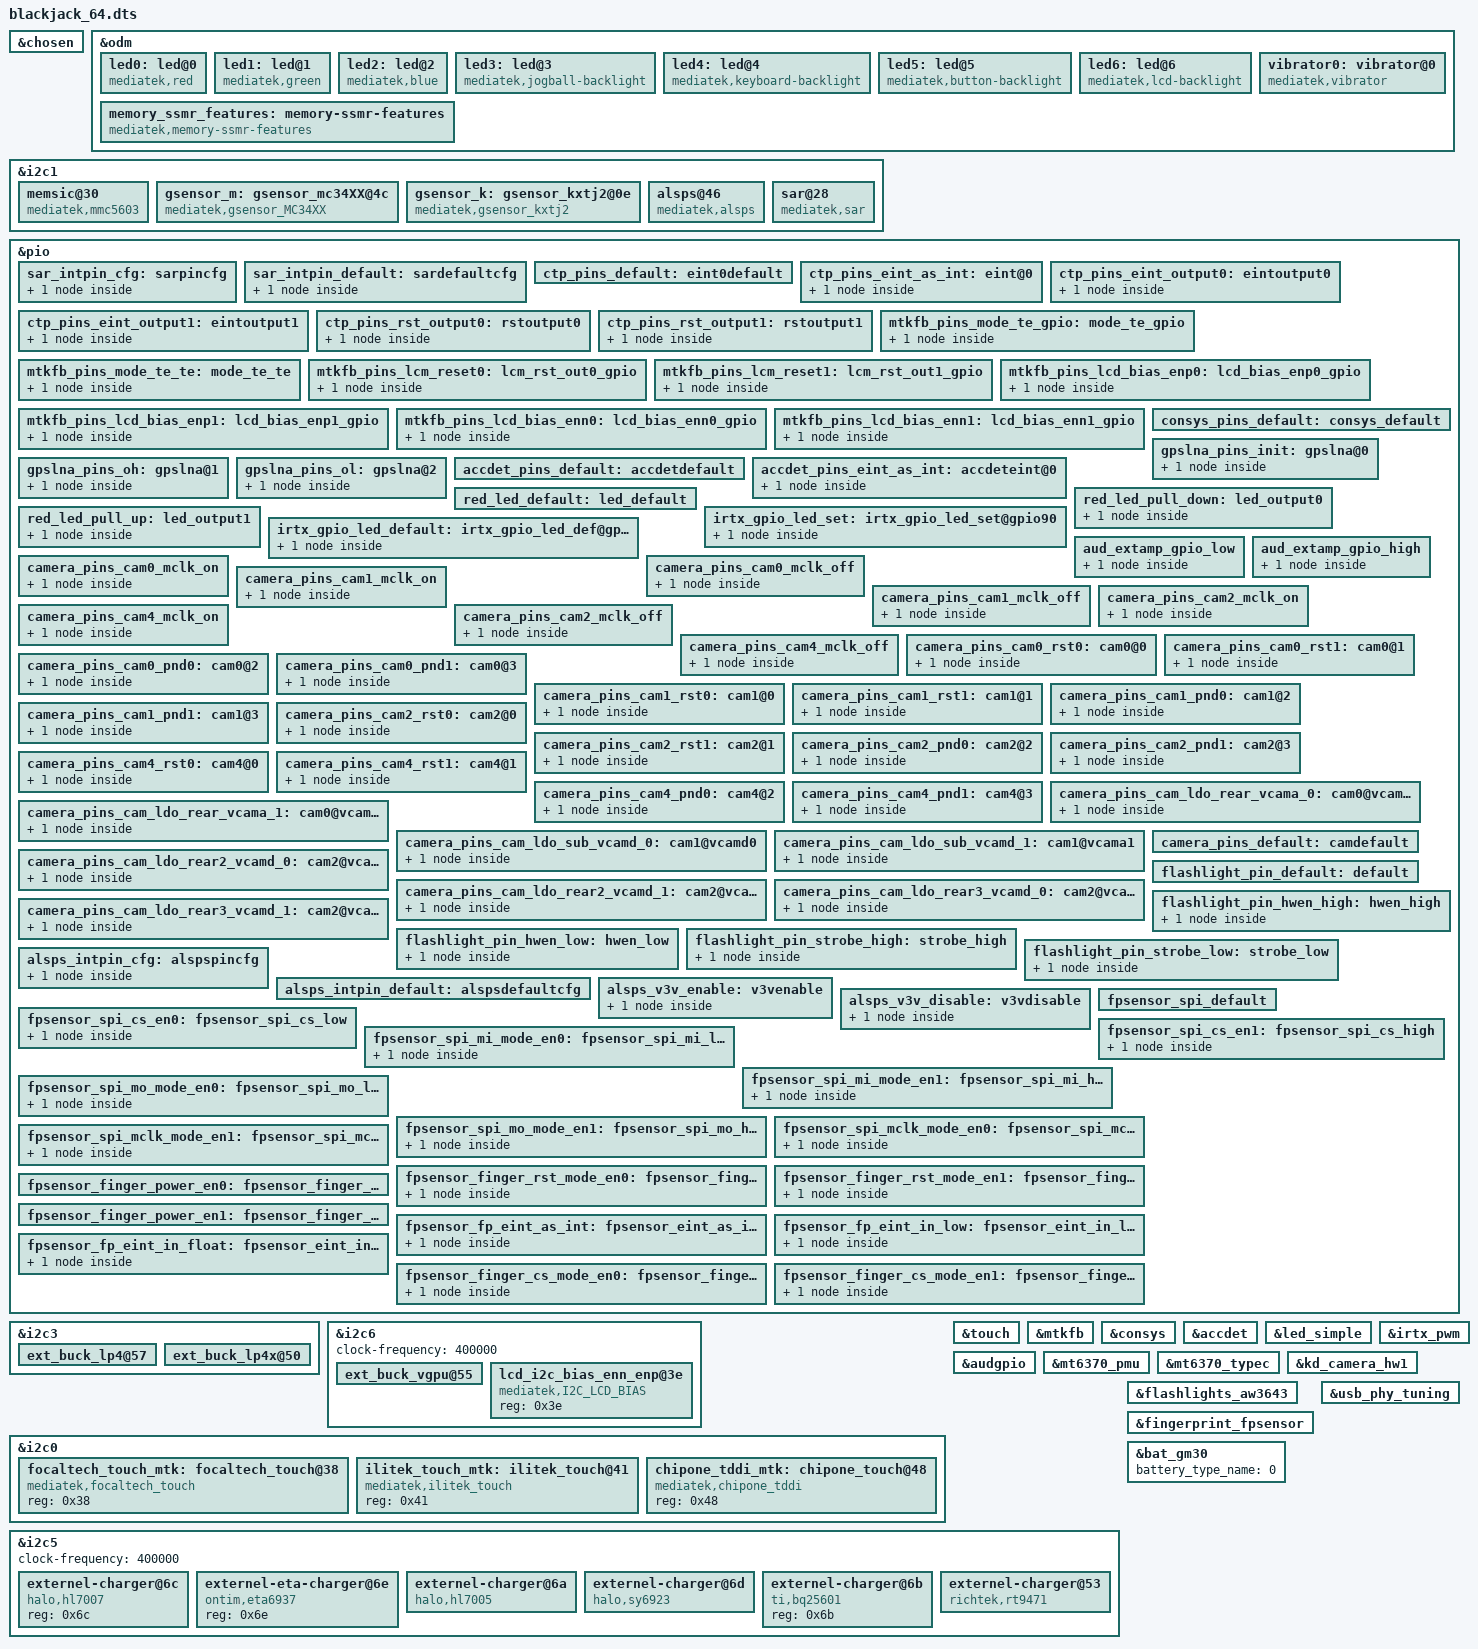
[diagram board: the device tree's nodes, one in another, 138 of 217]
#include <dt-bindings/interrupt-controller/arm-gic.h>
#include <dt-bindings/interrupt-controller/irq.h>
#include <dt-bindings/pinctrl/mt6765-pinfunc.h>
#include <dt-bindings/clock/mt6765-clk.h>

/dts-v1/;
/plugin/;

/* chosen */
&chosen {

	/* fpga may has no lk, we need to specify display info here */
	/* fb buffer is reserved using this dts by memory node above */
	atag,videolfb-fb_base_h = <0x0>;
	atag,videolfb-fb_base_l = <0x5e605000>;
	atag,videolfb-islcmfound = <1>;
	/* because no lk, so lcm is not inited */
	atag,videolfb-islcm_inited = <0>;
	atag,videolfb-fps= <6000>;
	atag,videolfb-vramSize= <0x017bb000>;
	atag,videolfb-lcmname= "nt35695B_fhd_dsi_cmd_auo_rt5081_drv";
};

&odm {
	led0:led@0 {
		compatible = "mediatek,red";
		led_mode = <3>;
		data = <1>;
		pwm_config = <0 0 0 0 0>;
	};
	led1:led@1 {
		compatible = "mediatek,green";
		led_mode = <3>;
		data = <2>;
		pwm_config = <0 0 0 0 0>;
	};
	led2:led@2 {
		compatible = "mediatek,blue";
		led_mode = <0>;
		data = <1>;
		pwm_config = <0 0 0 0 0>;
	};
	led3:led@3 {
		compatible = "mediatek,jogball-backlight";
		led_mode = <0>;
		data = <1>;
		pwm_config = <0 0 0 0 0>;
	};
	led4:led@4 {
		compatible = "mediatek,keyboard-backlight";
		led_mode = <0>;
		data = <1>;
		pwm_config = <0 0 0 0 0>;
	};
	led5:led@5 {
		compatible = "mediatek,button-backlight";
		led_mode = <0>;
		data = <1>;
		pwm_config = <0 0 0 0 0>;
	};
	led6:led@6 {
		compatible = "mediatek,lcd-backlight";
		led_mode = <4>;
		data = <1>;
		pwm_config = <0 2 0 0 0>;
	};
	vibrator0:vibrator@0 {
		compatible = "mediatek,vibrator";
		vib_timer = <25>;
		vib_limit = <9>;
		vib_vol= <0x0b>;
	};

	memory_ssmr_features: memory-ssmr-features {
		compatible = "mediatek,memory-ssmr-features";
		svp-size = <0 0x10000000>;
		iris-recognition-size = <0 0>;
		2d_fr-size = <0 0>;
		tui-size = <0 0>;
		wfd-size = <0 0>;
		prot-sharedmem-size = <0 0>;
	};

};

&i2c1 {
	#address-cells = <1>;
	#size-cells = <0>;

	/* magnetometer sensor */
	memsic@30 {
		compatible = "mediatek,mmc5603";
		reg = <0x30>;
		status = "okay";

		i2c_num = <1>;
		i2c_addr = <0x30 0 0 0>;
		direction = <2>;
		power_id = <0xffff>;
		power_vol = <0>;
		is_batch_supported = <0>;
	};

	gsensor_m:gsensor_mc34XX@4c {
		compatible = "mediatek,gsensor_MC34XX";
		reg = <0x4c>;
		status = "okay";

		i2c_num	= <1>;
		i2c_addr = <0x4c 0 0 0>;
		direction = <1>;
		power_id = <0xffff>;
		power_vol = <0>;
		firlen = <16>;
		is_batch_supported = <1>;
	};

	gsensor_k:gsensor_kxtj2@0e {
		compatible = "mediatek,gsensor_kxtj2";
		reg = <0x0e>;
		status = "okay";

		i2c_num	= <1>;
		i2c_addr = <0x0e 0 0 0>;
		direction = <6>;
		power_id = <0xffff>;
		power_vol = <0>;
		firlen = <16>;
		is_batch_supported = <1>;
	};

	alsps@46 {
		compatible = "mediatek,alsps";
		reg = <0x46>;
		status = "okay";

		pinctrl-names = "pin_default", "pin_cfg", "v3v_enable", "v3v_disable";
		pinctrl-0 = <&alsps_intpin_default>;
		pinctrl-1 = <&alsps_intpin_cfg>;
		pinctrl-2 = <&alsps_v3v_enable>;
		pinctrl-3 = <&alsps_v3v_disable>;

		i2c_num = <1>;
		i2c_addr = <0x46 0 0 0>;
		polling_mode_ps = <0>;
		polling_mode_als = <1>;
		power_id = <0xffff>;
		power_vol = <0>;
		als_level = < 
			0  128   300   482    930    1500    2750   3600
			0  145   335   570    1150   2700    3500   4800
			0  160   420   700    1200   2700    3900   5100
			0  128   300   482    930    1500    2750   3600
			0  145   335   570    1150   2700    3500   4800
			0  160   420   700    1200   2700    3900   5100
		>;
		als_value = < 0  133  304  502   1004  2005  3058   4000 >;
		state_val = <0>;
		psctrl_val = <0x31>;
		alsctrl_val = <0x38>;
		ledctrl_val = <0xFF>;
		wait_val = <0xF>;
		ps_threshold_high = <1700>;
		ps_threshold_low = <1500>;
		is_batch_supported_ps = <0>;
		is_batch_supported_als = <0>;
	};

	sar@28 {
		compatible = "mediatek,sar";
		reg = <0x28>;

		pinctrl-names = "pin_default", "pin_cfg";
		pinctrl-0 = <&sar_intpin_default>;
		pinctrl-1 = <&sar_intpin_cfg>;

		Semtech,reg-num = <46>; /* total registers number to initialize*/
		Semtech,reg-init  = /bits/ 8 < 0x10 0x16
						0x20 0x00
						0x23 0x00
						0x24 0x44
						0x26 0x01
						0x27 0x44
						0x28 0x01 /*PH0 to CS0 input*/
						0x29 0x10
						0x2A 0x19 /*PH2 CS2-input,CS1-dync,CS0-HZ*/
						0x2B 0x00
						0x2C 0x12
						0x2D 0x08
						0x30 0x09
						0x31 0x09
						0x32 0x08
						0x33 0x20
						0x34 0x0C
						0x35 0x00
						0x36 0x1B
						0x37 0x1B
						0x40 0x00
						0x41 0x00
						0x42 0x00
						0x43 0x00
						0x44 0x00
						0x45 0x05
						0x46 0x00
						0x47 0x00
						0x48 0x00
						0x49 0x80
						0x4A 0x00
						0x4B 0x00
						0x4C 0x00
						0x4D 0x00
						0x4E 0x80
						0x4F 0x0C
						0x50 0x00
						0x51 0x70
						0x52 0x20
						0x53 0xE1
						0x54 0xF0
						0x05 0x70
						0x06 0x00
						0x07 0x00
						0x08 0x00
						0x11 0x24>;
	};
};


&pio {
	sar_intpin_cfg: sarpincfg {
		pins_cmd_dat {
			pinmux = <PINMUX_GPIO9__FUNC_GPIO9>;
			slew-rate = <0>;
			bias-pull-up = <MTK_PUPD_SET_R1R0_01>;
		};
	};

	sar_intpin_default: sardefaultcfg {
		pins_cmd_dat {
			pinmux = <PINMUX_GPIO9__FUNC_GPIO9>;
			slew-rate = <0>;
			output-high;
		};
	};
};


&i2c3 {
	ext_buck_lp4@57 {
		regulator-name ="ext_buck_vdd2";
		regulator-min-microvolt = <300000>;
		regulator-max-microvolt = <1300000>;
		vsel_pin = <0>;
	};

	ext_buck_lp4x@50 {
		regulator-name ="ext_buck_vddq";
		regulator-min-microvolt = <300000>;
		regulator-max-microvolt = <1300000>;
		vsel_pin = <1>;
	};
};

&i2c6 {
	ext_buck_vgpu@55 {
		regulator-name ="ext_buck_vgpu";
		regulator-min-microvolt = <300000>;
		regulator-max-microvolt = <1300000>;
		vsel_pin = <2>;
	};
};
/* TOUCH start */
&i2c0 {
        #address-cells = <1>;
        #size-cells = <0>;
        clock-frequency = <400000>;
        mediatek,use-open-drain;
        focaltech_touch_mtk:focaltech_touch@38 {
                compatible = "mediatek,focaltech_touch";
                reg = <0x38>;
                status = "okay";
        };
        ilitek_touch_mtk:ilitek_touch@41 {
                compatible = "mediatek,ilitek_touch";
                reg = <0x41>;
                status = "okay";
        };
        chipone_tddi_mtk:chipone_touch@48 {
                compatible = "mediatek,chipone_tddi";
                reg = <0x48>;
                status = "okay";
        };

};

&touch {
	tpd-resolution = <720 1560>;
	use-tpd-button = <0>;
	tpd-key-num = <3>;
	tpd-key-local= <139 172 158 0>;
	tpd-key-dim-local = <90 883 100 40 230
				 883 100 40 370 883 100 40 0 0 0 0>;
	tpd-max-touch-num = <10>;
	tpd-filter-enable = <1>;
	tpd-filter-pixel-density = <106>;
	tpd-filter-custom-prameters = <0 0 0 0 0 0 0 0 0 0 0 0>;
	tpd-filter-custom-speed = <0 0 0>;
	pinctrl-names = "default", "state_eint_as_int", "state_eint_output0",
		"state_eint_output1", "state_rst_output0", "state_rst_output1";
	pinctrl-0 = <&ctp_pins_default>;
	pinctrl-1 = <&ctp_pins_eint_as_int>;
	pinctrl-2 = <&ctp_pins_eint_output0>;
	pinctrl-3 = <&ctp_pins_eint_output1>;
	pinctrl-4 = <&ctp_pins_rst_output0>;
	pinctrl-5 = <&ctp_pins_rst_output1>;
	status = "okay";
};
&pio {
	ctp_pins_default: eint0default {
	};
	ctp_pins_eint_as_int: eint@0 {
		pins_cmd_dat {
			pinmux = <PINMUX_GPIO0__FUNC_GPIO0>;
			slew-rate = <0>;
			bias-disable;
		};
	};
	ctp_pins_eint_output0: eintoutput0 {
		pins_cmd_dat {
			pinmux = <PINMUX_GPIO0__FUNC_GPIO0>;
			slew-rate = <1>;
			output-low;
		};
	};
	ctp_pins_eint_output1: eintoutput1 {
		pins_cmd_dat {
			pinmux = <PINMUX_GPIO0__FUNC_GPIO0>;
			slew-rate = <1>;
			output-high;
		};
	};
	ctp_pins_rst_output0: rstoutput0 {
		pins_cmd_dat {
			pinmux = <PINMUX_GPIO174__FUNC_GPIO174>;
			slew-rate = <1>;
			output-low;
		};
	};
	ctp_pins_rst_output1: rstoutput1 {
		pins_cmd_dat {
			pinmux = <PINMUX_GPIO174__FUNC_GPIO174>;
			slew-rate = <1>;
			output-high;
		};
	};
};
/* TOUCH end */

&i2c6 {
	#address-cells = <1>;
	#size-cells = <0>;
	clock-frequency = <400000>;

	lcd_i2c_bias_enn_enp@3e{
		compatible = "mediatek,I2C_LCD_BIAS";
		reg = <0x3e>;
		status = "okay";
	};
};

/* DISPSYS GPIO standardization */
&pio {
	mtkfb_pins_mode_te_gpio: mode_te_gpio {
		pins_cmd_dat {
			pinmux = <PINMUX_GPIO44__FUNC_DSI_TE>;
		};
	};

	mtkfb_pins_mode_te_te: mode_te_te {
		pins_cmd_dat {
			pinmux = <PINMUX_GPIO44__FUNC_DSI_TE>;
		};
	};

	mtkfb_pins_lcm_reset0: lcm_rst_out0_gpio {
		pins_cmd_dat {
			pinmux = <PINMUX_GPIO45__FUNC_GPIO45>;
			slew-rate = <1>;
			output-low;
		};
	};

	mtkfb_pins_lcm_reset1: lcm_rst_out1_gpio {
		pins_cmd_dat {
			pinmux = <PINMUX_GPIO45__FUNC_GPIO45>;
			slew-rate = <1>;
			output-high;
		};
	};

	mtkfb_pins_lcd_bias_enp0: lcd_bias_enp0_gpio {
		pins_cmd_dat {
			pinmux = <PINMUX_GPIO172__FUNC_GPIO172>;
			slew-rate = <1>;
			output-low;
		};
	};
	mtkfb_pins_lcd_bias_enp1: lcd_bias_enp1_gpio {
		pins_cmd_dat {
			pinmux = <PINMUX_GPIO172__FUNC_GPIO172>;
			slew-rate = <1>;
			output-high;
		};
	};

	mtkfb_pins_lcd_bias_enn0: lcd_bias_enn0_gpio {
		pins_cmd_dat {
			pinmux = <PINMUX_GPIO173__FUNC_GPIO173>;
			slew-rate = <1>;
			output-low;
		};
	};
	mtkfb_pins_lcd_bias_enn1: lcd_bias_enn1_gpio {
		pins_cmd_dat {
			pinmux = <PINMUX_GPIO173__FUNC_GPIO173>;
			slew-rate = <1>;
			output-high;
		};
	};

};

&mtkfb {
	pinctrl-names = "mode_te_gpio", "mode_te_te", "lcm_rst_out0_gpio",
		"lcm_rst_out1_gpio","lcd_bias_enp0_gpio", "lcd_bias_enp1_gpio", "lcd_bias_enn0_gpio", "lcd_bias_enn1_gpio";
	pinctrl-0 = <&mtkfb_pins_mode_te_gpio>;
	pinctrl-1 = <&mtkfb_pins_mode_te_te>;
	pinctrl-2 = <&mtkfb_pins_lcm_reset0>;
	pinctrl-3 = <&mtkfb_pins_lcm_reset1>;
	pinctrl-4 = <&mtkfb_pins_lcd_bias_enp0>;
	pinctrl-5 = <&mtkfb_pins_lcd_bias_enp1>;
	pinctrl-6 = <&mtkfb_pins_lcd_bias_enn0>;
	pinctrl-7 = <&mtkfb_pins_lcd_bias_enn1>;
	status = "okay";
};
/* DISPSYS GPIO standardization end */
/* CONSYS GPIO standardization */
&pio {
	consys_pins_default: consys_default {
	};
	gpslna_pins_init: gpslna@0 {
		pins_cmd_dat {
			pinmux = <PINMUX_GPIO91__FUNC_GPIO91>;
			slew-rate = <0>;
			bias-disable;
			output-low;
		};
	};
	gpslna_pins_oh: gpslna@1 {
		pins_cmd_dat {
			pinmux = <PINMUX_GPIO91__FUNC_GPIO91>;
			slew-rate = <1>;
			output-high;
		};
	};
	gpslna_pins_ol: gpslna@2 {
		pins_cmd_dat {
			pinmux = <PINMUX_GPIO91__FUNC_GPIO91>;
			slew-rate = <1>;
			output-low;
		};
	};
};
&consys {
	pinctrl-names = "default", "gps_lna_state_init",
		"gps_lna_state_oh", "gps_lna_state_ol";
	pinctrl-0 = <&consys_pins_default>;
	pinctrl-1 = <&gpslna_pins_init>;
	pinctrl-2 = <&gpslna_pins_oh>;
	pinctrl-3 = <&gpslna_pins_ol>;
	status = "okay";
};
/* CONSYS end */

/* accdet start */
&accdet {
	accdet-mic-vol = <6>;
	headset-mode-setting = <0x500 0x500 1 0x1f0 0x800 0x800 0x20 0x44>;
	accdet-plugout-debounce = <1>;
	accdet-mic-mode = <1>;
	headset-eint-level-pol = <8>;
	headset-three-key-threshold = <0 80 175 400>;
	headset-three-key-threshold-CDD = <0 121 192 600>;
	headset-four-key-threshold = <0 58 121 192 400>;
	pinctrl-names = "default", "state_eint_as_int";
	pinctrl-0 = <&accdet_pins_default>;
	pinctrl-1 = <&accdet_pins_eint_as_int>;
	status = "okay";
};
&pio {
	accdet_pins_default: accdetdefault {
	};
	accdet_pins_eint_as_int: accdeteint@0 {
		pins_cmd_dat {
			pinmux = <PINMUX_GPIO9__FUNC_GPIO9>;
			slew-rate = <0>;
			bias-disable;
		};
	};
};
/* accdet end */

&led_simple {
	pinctrl-names = "default", "red_led_output0", "red_led_output1";
	pinctrl-0 = <&red_led_default>;
	pinctrl-1 = <&red_led_pull_down>;
	pinctrl-2 = <&red_led_pull_up>;
	status = "okay";
};
&pio {
	red_led_default: led_default {
				 };
	red_led_pull_down: led_output0 {
		pins_cmd_dat {
			pinmux = <PINMUX_GPIO159__FUNC_GPIO159>;
			slew-rate = <1>;
			output-low;
		};
	};
	red_led_pull_up: led_output1 {
		pins_cmd_dat {
			pinmux = <PINMUX_GPIO159__FUNC_GPIO159>;
			slew-rate = <1>;
			output-high;
		};
	};
};
/* IRTX GPIO end */
&irtx_pwm {
	pinctrl-names = "irtx_gpio_led_default", "irtx_gpio_led_set";
	pinctrl-0 = <&irtx_gpio_led_default>;
	pinctrl-1 = <&irtx_gpio_led_set>;
	status = "okay";
};
&pio {
	irtx_gpio_led_default:irtx_gpio_led_def@gpio90 {
		pins_cmd_dat {
			pinmux = <PINMUX_GPIO90__FUNC_GPIO90>;
			slew-rate = <1>;
			bias-disable;
			output-low;
			input-schmitt-enable = <0>;
		};
	};

	irtx_gpio_led_set:irtx_gpio_led_set@gpio90 {
		pins_cmd_dat {
			pinmux = <PINMUX_GPIO90__FUNC_PWM0>;
			slew-rate = <1>;
			output-high;
		};
	};
};
/* IRTX GPIO Settings -End */

/* AUDIO GPIO standardization */
&audgpio {
		pinctrl-names = "extamp-pulllow",
				"extamp-pullhigh";
		pinctrl-0 = <&aud_extamp_gpio_low>;
		pinctrl-1 = <&aud_extamp_gpio_high>;
		status = "okay";
	};
	
	&pio {
	
		aud_extamp_gpio_low: aud_extamp_gpio_low {
			pins_gpio_low {
				pinmux = <PINMUX_GPIO153__FUNC_GPIO153>;
				out-enable;
				slew-rate = <2>;
				bias-disable;
				output-low;
			};
		};
	
		aud_extamp_gpio_high: aud_extamp_gpio_high {
			pins_gpio_high {
				pinmux = <PINMUX_GPIO153__FUNC_GPIO153>;
				out-enable;
				slew-rate = <2>;
				bias-disable;
				output-high;
			};
		};
};

/* AUDIO end */

&mt6370_pmu {
	mt6370,intr_gpio_num = <11>; /* direct defined GPIO num */
	mt6370,intr_gpio = <&pio 11 0x0>;
};

&mt6370_typec {
	mt6370pd,intr_gpio_num = <41>; /* direct defined GPIO num */
	mt6370pd,intr_gpio = <&pio 41 0x0>;
};

&i2c5 {
	#address-cells = <1>;
	#size-cells = <0>;
	clock-frequency = <400000>;

	externel-charger@6c{
		compatible = "halo,hl7007";
		reg = <0x6c>;
		status = "okay";
	};
       externel-eta-charger@6e{
               compatible = "ontim,eta6937";
               reg = <0x6e>;/*dumy addr,in fact ,the addr is 0x6b-1*/
               status = "okay";
       };
	externel-charger@6a{
		compatible = "halo,hl7005";
		reg = <0x6a>;
		status = "okay";
		ichg = <1050000>; /* uA */
	};
	externel-charger@6d{
		compatible = "halo,sy6923";
		reg = <0x6d>;
		status = "okay";
		ichg = <1050000>; /* uA */
	};
	externel-charger@6b{
		compatible = "ti,bq25601";
		reg = <0x6b>;
		status = "okay";
	};
	externel-charger@53{
		compatible = "richtek,rt9471";
		reg = <0x53>;
		status = "okay";
		ichg = <2000000>; /* uA */
	};
};
&pio {
	camera_pins_cam0_mclk_on: camera_pins_cam0_mclk_on {
		pins_cmd_dat {
			pinmux = <PINMUX_GPIO99__FUNC_CMMCLK0>;
		};
	};
	camera_pins_cam0_mclk_off: camera_pins_cam0_mclk_off {
		pins_cmd_dat {
			pinmux = <PINMUX_GPIO99__FUNC_GPIO99>;
		};
	};
	camera_pins_cam1_mclk_on: camera_pins_cam1_mclk_on {
		pins_cmd_dat {
			pinmux = <PINMUX_GPIO100__FUNC_CMMCLK1>;
		};
	};
	camera_pins_cam1_mclk_off: camera_pins_cam1_mclk_off {
		pins_cmd_dat {
			pinmux = <PINMUX_GPIO100__FUNC_GPIO100>;
		};
	};
	camera_pins_cam2_mclk_on: camera_pins_cam2_mclk_on {
		pins_cmd_dat {
			pinmux = <PINMUX_GPIO88__FUNC_CMMCLK3>;
		};
	};
	camera_pins_cam2_mclk_off: camera_pins_cam2_mclk_off {
		pins_cmd_dat {
			pinmux = <PINMUX_GPIO88__FUNC_GPIO88>;
		};
	};
	camera_pins_cam4_mclk_on: camera_pins_cam4_mclk_on {
		pins_cmd_dat {
			pinmux = <PINMUX_GPIO108__FUNC_CMMCLK2>;
		};
	};
	camera_pins_cam4_mclk_off: camera_pins_cam4_mclk_off {
		pins_cmd_dat {
			pinmux = <PINMUX_GPIO108__FUNC_GPIO108>;
		};
	};
	camera_pins_cam0_rst0: cam0@0 {
		pins_cmd_dat {
			pinmux = <PINMUX_GPIO101__FUNC_GPIO101>;
			slew-rate = <1>;
			output-low;
		};
	};
	camera_pins_cam0_rst1: cam0@1 {
		pins_cmd_dat {
			pinmux = <PINMUX_GPIO101__FUNC_GPIO101>;
			slew-rate = <1>;
			output-high;
		};
	};
	camera_pins_cam0_pnd0: cam0@2 {
		pins_cmd_dat {
			pinmux = <PINMUX_GPIO97__FUNC_GPIO97>;
			slew-rate = <1>;
			output-low;
		};
	};
	camera_pins_cam0_pnd1: cam0@3 {
		pins_cmd_dat {
			pinmux = <PINMUX_GPIO97__FUNC_GPIO97>;
			slew-rate = <1>;
			output-high;
		};
	};
	camera_pins_cam1_rst0: cam1@0 {
		pins_cmd_dat {
			pinmux = <PINMUX_GPIO102__FUNC_GPIO102>;
			slew-rate = <1>;
			output-low;
		};
	};
	camera_pins_cam1_rst1: cam1@1 {
		pins_cmd_dat {
			pinmux = <PINMUX_GPIO102__FUNC_GPIO102>;
			slew-rate = <1>;
			output-high;
		};
	};
	camera_pins_cam1_pnd0: cam1@2 {
		pins_cmd_dat {
			pinmux = <PINMUX_GPIO98__FUNC_GPIO98>;
			slew-rate = <1>;
			output-low;
		};
	};
	camera_pins_cam1_pnd1: cam1@3 {
		pins_cmd_dat {
			pinmux = <PINMUX_GPIO98__FUNC_GPIO98>;
			slew-rate = <1>;
			output-high;
		};
	};
	camera_pins_cam2_rst0: cam2@0 {
		pins_cmd_dat {
			pinmux = <PINMUX_GPIO87__FUNC_GPIO87>;
			slew-rate = <1>;
			output-low;
		};
	};
	camera_pins_cam2_rst1: cam2@1 {
		pins_cmd_dat {
			pinmux = <PINMUX_GPIO87__FUNC_GPIO87>;
			slew-rate = <1>;
			output-high;
		};
	};
	camera_pins_cam2_pnd0: cam2@2 {
		pins_cmd_dat {
			pinmux = <PINMUX_GPIO160__FUNC_GPIO160>;
			slew-rate = <1>;
			output-low;
		};
	};
	camera_pins_cam2_pnd1: cam2@3 {
		pins_cmd_dat {
			pinmux = <PINMUX_GPIO160__FUNC_GPIO160>;
			slew-rate = <1>;
			output-high;
		};
	};
	camera_pins_cam4_rst0: cam4@0 {
		pins_cmd_dat {
			pinmux = <PINMUX_GPIO109__FUNC_GPIO109>;
			slew-rate = <1>;
			output-low;
		};
	};
	camera_pins_cam4_rst1: cam4@1 {
		pins_cmd_dat {
			pinmux = <PINMUX_GPIO109__FUNC_GPIO109>;
			slew-rate = <1>;
			output-high;
		};
	};
	camera_pins_cam4_pnd0: cam4@2 {
		pins_cmd_dat {
			pinmux = <PINMUX_GPIO107__FUNC_GPIO107>;
			slew-rate = <1>;
			output-low;
		};
	};
	camera_pins_cam4_pnd1: cam4@3 {
		pins_cmd_dat {
			pinmux = <PINMUX_GPIO107__FUNC_GPIO107>;
			slew-rate = <1>;
			output-high;
		};
	};
	camera_pins_cam_ldo_rear_vcama_0: cam0@vcamd0 {
		pins_cmd_dat {
			pinmux = <PINMUX_GPIO21__FUNC_GPIO21>;
			slew-rate = <1>;
			output-low;
		};
	};
	camera_pins_cam_ldo_rear_vcama_1: cam0@vcamd1 {
		pins_cmd_dat {
			pinmux = <PINMUX_GPIO21__FUNC_GPIO21>;
			slew-rate = <1>;
			output-high;
		};
	};
	camera_pins_cam_ldo_sub_vcamd_0: cam1@vcamd0 {
		pins_cmd_dat {
			pinmux = <PINMUX_GPIO24__FUNC_GPIO24>;
			slew-rate = <1>;
			output-low;
		};
	};
	camera_pins_cam_ldo_sub_vcamd_1: cam1@vcama1 {
		pins_cmd_dat {
			pinmux = <PINMUX_GPIO24__FUNC_GPIO24>;
			slew-rate = <1>;
			output-high;
		};
	};
	camera_pins_cam_ldo_rear2_vcamd_0: cam2@vcama0 {
		pins_cmd_dat {
			pinmux = <PINMUX_GPIO24__FUNC_GPIO24>;
			slew-rate = <1>;
			output-low;
		};
	};
	camera_pins_cam_ldo_rear2_vcamd_1: cam2@vcama1 {
		pins_cmd_dat {
			pinmux = <PINMUX_GPIO24__FUNC_GPIO24>;
			slew-rate = <1>;
			output-high;
		};
	};
	camera_pins_cam_ldo_rear3_vcamd_0: cam2@vcamd0 {
		pins_cmd_dat {
			pinmux = <PINMUX_GPIO24__FUNC_GPIO24>;
			slew-rate = <1>;
			output-low;
		};
	};
	camera_pins_cam_ldo_rear3_vcamd_1: cam2@vcamd1 {
		pins_cmd_dat {
			pinmux = <PINMUX_GPIO24__FUNC_GPIO24>;
			slew-rate = <1>;
			output-high;
		};
	};
	camera_pins_default: camdefault {
	};

};

&kd_camera_hw1 {
	pinctrl-names = "default",
			"cam0_rst0",
			"cam0_rst1",
			"cam0_pnd0",
			"cam0_pnd1",
			"cam1_rst0",
			"cam1_rst1",
			"cam1_pnd0",
			"cam1_pnd1",
			"cam2_rst0",
			"cam2_rst1",
			"cam2_pnd0",
			"cam2_pnd1",
			"cam4_rst0",
			"cam4_rst1",
			"cam4_pnd0",
			"cam4_pnd1",
			"cam0_vcama_on",
			"cam0_vcama_off",
			"cam1_vcamd_on",
			"cam1_vcamd_off",
			"cam2_vcamd_on",
			"cam2_vcamd_off",
			"cam4_vcamd_on",
			"cam4_vcamd_off",
			"cam0_mclk_on",
			"cam0_mclk_off",
			"cam1_mclk_on",
			"cam1_mclk_off",
			"cam2_mclk_on",
			"cam2_mclk_off",
			"cam4_mclk_on",
			"cam4_mclk_off";

	pinctrl-0 = <&camera_pins_default>;
	pinctrl-1 = <&camera_pins_cam0_rst0>;
	pinctrl-2 = <&camera_pins_cam0_rst1>;
	pinctrl-3 = <&camera_pins_cam0_pnd0>;
	pinctrl-4 = <&camera_pins_cam0_pnd1>;
	pinctrl-5 = <&camera_pins_cam1_rst0>;
	pinctrl-6 = <&camera_pins_cam1_rst1>;
	pinctrl-7 = <&camera_pins_cam1_pnd0>;
	pinctrl-8 = <&camera_pins_cam1_pnd1>;
	pinctrl-9 = <&camera_pins_cam2_rst0>;
	pinctrl-10 = <&camera_pins_cam2_rst1>;
	pinctrl-11 = <&camera_pins_cam2_pnd0>;
	pinctrl-12 = <&camera_pins_cam2_pnd1>;
	pinctrl-13 = <&camera_pins_cam4_rst0>;
	pinctrl-14 = <&camera_pins_cam4_rst1>;
	pinctrl-15 = <&camera_pins_cam4_pnd0>;
	pinctrl-16 = <&camera_pins_cam4_pnd1>;
	pinctrl-17 = <&camera_pins_cam_ldo_rear_vcama_1>;
	pinctrl-18 = <&camera_pins_cam_ldo_rear_vcama_0>;
	pinctrl-19 = <&camera_pins_cam_ldo_sub_vcamd_1>;
	pinctrl-20 = <&camera_pins_cam_ldo_sub_vcamd_0>;
	pinctrl-21 = <&camera_pins_cam_ldo_rear2_vcamd_1>;
	pinctrl-22 = <&camera_pins_cam_ldo_rear2_vcamd_0>;
	pinctrl-23 = <&camera_pins_cam_ldo_rear3_vcamd_1>;
	pinctrl-24 = <&camera_pins_cam_ldo_rear3_vcamd_0>;
	pinctrl-25 = <&camera_pins_cam0_mclk_on>;
	pinctrl-26 = <&camera_pins_cam0_mclk_off>;
	pinctrl-27 = <&camera_pins_cam1_mclk_on>;
	pinctrl-28 = <&camera_pins_cam1_mclk_off>;
	pinctrl-29 = <&camera_pins_cam2_mclk_on>;
	pinctrl-30 = <&camera_pins_cam2_mclk_off>;
	pinctrl-31 = <&camera_pins_cam4_mclk_on>;
	pinctrl-32 = <&camera_pins_cam4_mclk_off>;
	status = "okay";

};
 /* flashlight begin */
 
&pio{
     flashlight_pin_default: default{};

     flashlight_pin_hwen_high: hwen_high{
         pins_cmd_dat {
             pinmux = <PINMUX_GPIO151__FUNC_GPIO151>;
             slew-rate = <1>;
             output-high;
         };
    };

     flashlight_pin_hwen_low: hwen_low{
         pins_cmd_dat{
             pinmux = <PINMUX_GPIO151__FUNC_GPIO151>;
             slew-rate = <1>;
            output-low;
         };
     };
     flashlight_pin_strobe_high: strobe_high{
         pins_cmd_dat {
             pinmux = <PINMUX_GPIO150__FUNC_GPIO150>;
             slew-rate = <1>;
             output-high;
         };
     };

     flashlight_pin_strobe_low: strobe_low{
         pins_cmd_dat{
             pinmux = <PINMUX_GPIO150__FUNC_GPIO150>;
             slew-rate = <1>;
             output-low;
         };
     };
};

&flashlights_aw3643{
     pinctrl-names = "default", "hwen_high", "hwen_low", "strobe_high", "strobe_low";
     pinctrl-0 = <&flashlight_pin_default>;
     pinctrl-1 = <&flashlight_pin_hwen_high>;
     pinctrl-2 = <&flashlight_pin_hwen_low>;
     pinctrl-3 = <&flashlight_pin_strobe_high>;
     pinctrl-4 = <&flashlight_pin_strobe_low>;
     status = "okay";
};

&pio {
        alsps_intpin_cfg: alspspincfg {

                pins_cmd_dat {
                        pinmux = <PINMUX_GPIO6__FUNC_GPIO6>;
                        slew-rate = <0>;
                        bias-pull-up = <MTK_PUPD_SET_R1R0_01>;
                };
        };

        alsps_intpin_default: alspsdefaultcfg {

        };

        alsps_v3v_enable: v3venable {
                pins_cmd_dat {
                        pinmux = <PINMUX_GPIO154__FUNC_GPIO154>;
                        slew-rate = <1>;
                        output-high;
                };
        };
        alsps_v3v_disable: v3vdisable {
                pins_cmd_dat {
                        pinmux = <PINMUX_GPIO154__FUNC_GPIO154>;
                        slew-rate = <1>;
                        output-low;
                };
        };
};
&pio{
	fpsensor_spi_default: fpsensor_spi_default {
	};

	fpsensor_spi_cs_en0: fpsensor_spi_cs_low {
		pins_cmd_dat {
			pinmux = <PINMUX_GPIO26__FUNC_SPI1_A_CSB>;
			slew-rate = <1>;
			output-low;
		};
	};
	fpsensor_spi_cs_en1: fpsensor_spi_cs_high {
		pins_cmd_dat {
			pinmux = <PINMUX_GPIO26__FUNC_SPI1_A_CSB>;
			slew-rate = <1>;
			output-high;
		};
	};
	fpsensor_spi_mi_mode_en0: fpsensor_spi_mi_low {
		pins_cmd_dat {
			pinmux = <PINMUX_GPIO25__FUNC_SPI1_A_MI>;
			slew-rate = <0>;
			bias-pull-up = <00>;
		};
	};
	fpsensor_spi_mi_mode_en1: fpsensor_spi_mi_high {
		pins_cmd_dat {
			pinmux = <PINMUX_GPIO25__FUNC_SPI1_A_MI>;
			bias-disable;
		};
	};
	fpsensor_spi_mo_mode_en0: fpsensor_spi_mo_low {
		pins_cmd_dat {
			pinmux = <PINMUX_GPIO27__FUNC_SPI1_A_MO>;
			slew-rate = <1>;
			output-low;
		};
	};
	fpsensor_spi_mo_mode_en1: fpsensor_spi_mo_high {
		pins_cmd_dat {
			pinmux = <PINMUX_GPIO27__FUNC_SPI1_A_MO>;
			slew-rate = <1>;
			output-high;
		};
	};
	fpsensor_spi_mclk_mode_en0: fpsensor_spi_mclk_low {
		pins_cmd_dat {
			pinmux = <PINMUX_GPIO28__FUNC_SPI1_A_CLK>;
			slew-rate = <1>;
			output-low;
		};
	};
	fpsensor_spi_mclk_mode_en1: fpsensor_spi_mclk_high {
		pins_cmd_dat {
			pinmux = <PINMUX_GPIO28__FUNC_SPI1_A_CLK>;
			slew-rate = <1>;
			output-high;
		};
	};
	fpsensor_finger_rst_mode_en0: fpsensor_finger_rst_low {
		pins_cmd_dat {
			pinmux = <PINMUX_GPIO22__FUNC_GPIO22>;
			slew-rate = <1>;
			output-low;
		};
	};
	fpsensor_finger_rst_mode_en1: fpsensor_finger_rst_high {
		pins_cmd_dat {
			pinmux = <PINMUX_GPIO22__FUNC_GPIO22>;
			slew-rate = <1>;
			output-high;
		};
	};
	fpsensor_finger_power_en0: fpsensor_finger_power_low {
	};

	fpsensor_finger_power_en1: fpsensor_finger_power_high {
	};

	fpsensor_fp_eint_as_int: fpsensor_eint_as_int {
		pins_cmd_dat {
			pinmux = <PINMUX_GPIO5__FUNC_GPIO5>;
			slew-rate = <0>;
			//bias-disable;
			bias-pull-down = <00>;
		};
	};
	fpsensor_fp_eint_in_low: fpsensor_eint_in_low {
		pins_cmd_dat {
			pinmux = <PINMUX_GPIO5__FUNC_GPIO5>;
			slew-rate = <0>;
			bias-pull-down = <00>;
		};
	};
	fpsensor_fp_eint_in_float: fpsensor_eint_in_float {
		pins_cmd_dat {
			pinmux = <PINMUX_GPIO5__FUNC_GPIO5>;
			slew-rate = <0>;
			bias-disable;
		};
	};
	fpsensor_finger_cs_mode_en0: fpsensor_finger_cs_low {
		pins_cmd_dat {
			pinmux = <PINMUX_GPIO26__FUNC_SPI1_A_CSB>;
			slew-rate = <1>;
			output-low;
			input-schmitt-enable = <0>;
		};
	};
	fpsensor_finger_cs_mode_en1: fpsensor_finger_cs_high {
		pins_cmd_dat {
			pinmux = <PINMUX_GPIO26__FUNC_SPI1_A_CSB>;
			slew-rate = <1>;
			output-high;
			input-schmitt-enable = <0>;
		 };
	};
};

&fingerprint_fpsensor{
	pinctrl-names = "fpsensor_spi_default", "fpsensor_spi_cs_low","fpsensor_spi_cs_high","fpsensor_spi_mi_low","fpsensor_spi_mi_high",
		"fpsensor_spi_mo_low","fpsensor_spi_mo_high","fpsensor_spi_mclk_low","fpsensor_spi_mclk_high",
		"fpsensor_finger_rst_low","fpsensor_finger_rst_high","fpsensor_finger_power_low","fpsensor_finger_power_high",
		"fpsensor_eint_as_int","fpsensor_eint_in_low","fpsensor_eint_in_float","fpsensor_finger_cs_low","fpsensor_finger_cs_high";

	pinctrl-0 = <&fpsensor_spi_default>;
	pinctrl-1 = <&fpsensor_spi_cs_en0>;
	pinctrl-2 = <&fpsensor_spi_cs_en1>;
	pinctrl-3 = <&fpsensor_spi_mi_mode_en0>;
	pinctrl-4 = <&fpsensor_spi_mi_mode_en1>;
	pinctrl-5 = <&fpsensor_spi_mo_mode_en0>;
	pinctrl-6 = <&fpsensor_spi_mo_mode_en1>;
	pinctrl-7 = <&fpsensor_spi_mclk_mode_en0>;
	pinctrl-8 = <&fpsensor_spi_mclk_mode_en1>;

	pinctrl-9 = <&fpsensor_finger_rst_mode_en0>;
	pinctrl-10 = <&fpsensor_finger_rst_mode_en1>;
	pinctrl-11 = <&fpsensor_finger_power_en0>;
	pinctrl-12 = <&fpsensor_finger_power_en1>;
	pinctrl-13 = <&fpsensor_fp_eint_as_int>;
	pinctrl-14 = <&fpsensor_fp_eint_in_low>;
	pinctrl-15 = <&fpsensor_fp_eint_in_float>;
	pinctrl-16 = <&fpsensor_finger_cs_mode_en0>;
	pinctrl-17 = <&fpsensor_finger_cs_mode_en1>;

	status = "okay";
};
&bat_gm30{
	battery_type_name = <0>;
};

&usb_phy_tuning{
	u2_vrt_ref = <7>;
	u2_term_ref = <6>;
	u2_host_vrt_ref = <4>;
	u2_host_term_ref = <4>;
	status = "okay";
};

#include "bat_setting/mt6765_battery_table_blackjack.dtsi"
#include "bat_setting/mt6765_battery_table_blackjack_2.dtsi"
#include "bat_setting/mt6765_battery_table_blackjack_3.dtsi"

#include <blackjack_64/cust.dtsi>
/*End of this file, DO NOT ADD ANYTHING HERE*/
